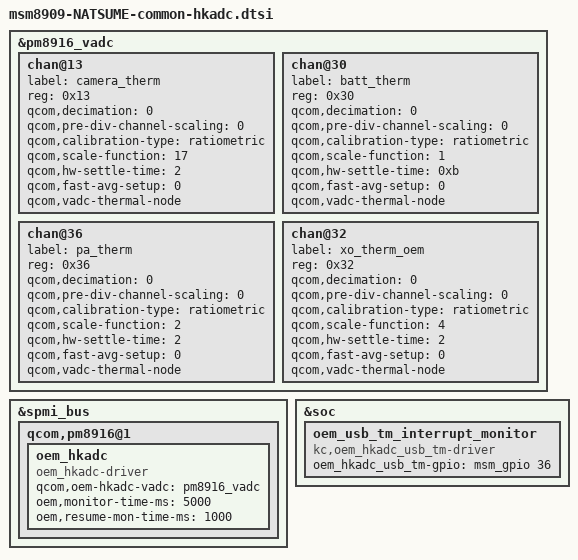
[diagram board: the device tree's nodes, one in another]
/*
 * This software is contributed or developed by KYOCERA Corporation.
 * (C) 2019 KYOCERA Corporation
 *
 * This program is free software; you can redistribute it and/or modify
 * it under the terms of the GNU General Public License version 2 and
 * only version 2 as published by the Free Software Foundation.
 *
 * This program is distributed in the hope that it will be useful,
 * but WITHOUT ANY WARRANTY; without even the implied warranty of
 * MERCHANTABILITY or FITNESS FOR A PARTICULAR PURPOSE.  See the
 * GNU General Public License for more details.
 */

&pm8916_vadc {
	chan@13 {
		label = "camera_therm";
		reg = <0x13>;
		qcom,decimation = <0>;
		qcom,pre-div-channel-scaling = <0>;
		qcom,calibration-type = "ratiometric";
		qcom,scale-function = <17>;
		qcom,hw-settle-time = <2>;
		qcom,fast-avg-setup = <0>;
		qcom,vadc-thermal-node;
	};

	chan@30 {
		label = "batt_therm";
		reg = <0x30>;
		qcom,decimation = <0>;
		qcom,pre-div-channel-scaling = <0>;
		qcom,calibration-type = "ratiometric";
		qcom,scale-function = <1>;
		qcom,hw-settle-time = <0xb>;
		qcom,fast-avg-setup = <0>;
		qcom,vadc-thermal-node;
	};

	chan@36 {
		label = "pa_therm";
		reg = <0x36>;
		qcom,decimation = <0>;
		qcom,pre-div-channel-scaling = <0>;
		qcom,calibration-type = "ratiometric";
		qcom,scale-function = <2>;
		qcom,hw-settle-time = <2>;
		qcom,fast-avg-setup = <0>;
		qcom,vadc-thermal-node;
	};

	chan@32 {
		label = "xo_therm_oem";
		reg = <0x32>;
		qcom,decimation = <0>;
		qcom,pre-div-channel-scaling = <0>;
		qcom,calibration-type = "ratiometric";
		qcom,scale-function = <4>;
		qcom,hw-settle-time = <2>;
		qcom,fast-avg-setup = <0>;
		qcom,vadc-thermal-node;
	};
};

&spmi_bus {
	qcom,pm8916@1 {
		oem_hkadc {
			compatible = "oem_hkadc-driver";
			qcom,oem-hkadc-vadc = <&pm8916_vadc>;
			oem,monitor-time-ms = <5000>;
			oem,resume-mon-time-ms = <1000>;
		};
	};
};

&soc {
	oem_usb_tm_interrupt_monitor {
		compatible = "kc,oem_hkadc_usb_tm-driver";
		oem_hkadc_usb_tm-gpio = <&msm_gpio 36 0x00>;
	};
};
